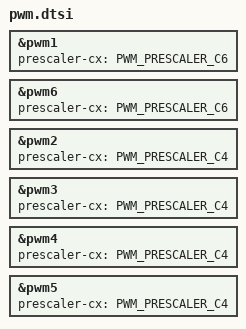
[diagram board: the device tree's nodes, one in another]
/* Copyright 2024 The ChromiumOS Authors
 * Use of this source code is governed by a BSD-style license that can be
 * found in the LICENSE file.
 */

/* Keyboard backlight and fan - use a prescaler for operation about 324 Hz */
/* Keyboard */
&pwm1 {
	prescaler-cx = <PWM_PRESCALER_C6>;
};

/* Fan */
&pwm6 {
	prescaler-cx = <PWM_PRESCALER_C6>;
};

/* Board LEDs - share one prescaler reference, all clocks must be configured
 * for 324 Hz or lower so LEDs work in low power mode.
 */
&pwm2 {
	prescaler-cx = <PWM_PRESCALER_C4>;
};

&pwm3 {
	prescaler-cx = <PWM_PRESCALER_C4>;
};

&pwm4 {
	prescaler-cx = <PWM_PRESCALER_C4>;
};

&pwm5 {
	prescaler-cx = <PWM_PRESCALER_C4>;
};
